AUTOSAR XML (schema 4-0-3)
standard types defined: boolean, float32, float64, sint16, sint32, sint8, uint16, uint32, uint8
package /BSWScheduler/BswImplementations
  bsw implementation bswImplementation0: programming-language=C, sw-version=1.0.0, vendor-id=20, ar-release-version=1.0.0, behavior=Com/InternalBehavior_0, vendor-api-infix=abc
    code-descriptors:
      code Code: artifact-descriptors=autosar-engineering-object={short-label=Label, category=Category}
    resource consumption resourceConsumption
  bsw implementation bswImplementation1: programming-language=C, sw-version=1.0.0, vendor-id=20, ar-release-version=1.0.0, behavior=Can/InternalBehavior_0, vendor-api-infix=abc
    code-descriptors:
      code Code: artifact-descriptors=autosar-engineering-object={short-label=Label, category=Category}
    resource consumption resourceConsumption
  bsw implementation bswImplementation2: programming-language=C, sw-version=1.0.0, vendor-id=20, ar-release-version=1.0.0, behavior=CanIf/InternalBehavior_0, vendor-api-infix=abc
    code-descriptors:
      code Code: artifact-descriptors=autosar-engineering-object={short-label=Label, category=Category}
    resource consumption resourceConsumption
package /BSWScheduler/BswModuleDescriptions
  bsw module description Can: module-id=80, provided-entrys=BswModuleEntryDummy0
    bsw internal behavior InternalBehavior_0
      exclusive area Reentrant
      bsw schedulable entity BswSchedulableEntityDummy: can-enter-exclusive-area=Reentrant, implemented-entry=BswModuleEntryDummy0
  bsw module description CanIf: module-id=60, provided-entrys=BswModuleEntryDummy1
    bsw internal behavior InternalBehavior_0
      exclusive area Reentrant_0
      exclusive area Reentrant_1
      bsw schedulable entity BswSchedulableEntityDummy: can-enter-exclusive-area=[InternalBehavior_0/Reentrant_0, InternalBehavior_0/Reentrant_1], implemented-entry=BswModuleEntryDummy1
  bsw module description Com: module-id=50, provided-entrys=[MainFunctionRx, MainFunctionTx]
    bsw internal behavior InternalBehavior_0
      exclusive area Reentrant_{0..2}
      bsw schedulable entity MainFunctionRx: can-enter-exclusive-area=[InternalBehavior_0/Reentrant_0, InternalBehavior_0/Reentrant_1, Reentrant_2], implemented-entry=MainFunctionRx
      bsw schedulable entity MainFunctionTx: can-enter-exclusive-area=[InternalBehavior_0/Reentrant_0, InternalBehavior_0/Reentrant_1, Reentrant_2], implemented-entry=MainFunctionTx
      bsw timing event TimingEvent_MainFunctionRx: starts-on-event=MainFunctionRx, period=0.1
      bsw timing event TimingEvent_MainFunctionTx: starts-on-event=MainFunctionTx, period=0.1
package /BSWScheduler/BswModuleEntrys
  4 x bsw module entry, all with is-synchronous=true, call-type=SCHEDULED, execution-context=TASK, sw-service-impl-policy=STANDARD:
    BswModuleEntryDummy0: is-reentrant=true
    BswModuleEntryDummy1: is-reentrant=true
    MainFunctionRx: service-id=24, is-reentrant=false
    MainFunctionTx: service-id=25, is-reentrant=false
package /HelloAutosar
  composition sw component type HA_TopLevel
    component SWC1: type=SWC1
    component SWC2: type=SWC2
    connect SWC1.PPort -> SWC2.RPort
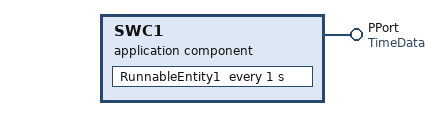
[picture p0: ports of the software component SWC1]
  application sw component type SWC1
    provide port PPort: nonqueued-sender-com-spec{data-element=time, transmission-acknowledge=timeout=0, init-value=Value:0}, provided-interface=TimeData
    behavior IB_SWC1: handle-termination-and-restart=NO-SUPPORT
      timing event TimingEvent: start-on-event=RunnableEntity1, period=1
      runnable RunnableEntity1
        data-send-points:
          access VariableAccess: accessed-variable=PPort.time
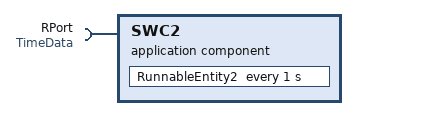
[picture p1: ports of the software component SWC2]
  application sw component type SWC2
    require port RPort: nonqueued-receiver-com-spec{data-element=time, alive-timeout=10, enable-update=true, init-value=Value:0}, required-interface=TimeData
    behavior IB_SWC2: handle-termination-and-restart=NO-SUPPORT
      timing event TimingEvent: start-on-event=RunnableEntity2, period=1
      runnable RunnableEntity2
        data-receive-point-by-arguments:
          access VariableAccess: accessed-variable=RPort.time
package /ImplDataTypes
  impl type IDT_TimeCount: category=VALUE, base-type=uint32
package /Interfaces
  sender receiver interface TimeData
    data time: type=IDT_TimeCount
package /Network
  pdu ISignalIPdu1: unused-bit-pattern=0
    signal ISignal1: 32 bit, data-type-policy=PORT-INTERFACE-DEFINITION
package /System
  ecu instance EcuInstance1: com-configuration-gw-time-base=0.1, com-configuration-rx-time-base=0.1, com-configuration-tx-time-base=0.1, sleep-mode-supported=false, wake-up-over-bus-supported=false
    can communication controller CanCommunicationController: can-controller-attributes=can-controller-configuration={sync-jump-width=1, time-seg-1=1, time-seg-2=1}
  ecu instance EcuInstance2: com-configuration-gw-time-base=0.1, com-configuration-rx-time-base=0.1, com-configuration-tx-time-base=0.1, sleep-mode-supported=false, wake-up-over-bus-supported=false
    can communication controller CanCommunicationController: can-controller-attributes=can-controller-configuration={sync-jump-width=1, time-seg-1=1, time-seg-2=1}
  ecuc value collection EcucValueCollection: ecu-extract=SystemHA, ecuc-values=[Os, Rte, Com, EcuC]
  system SystemHA: system-version=1.0.0
    system mapping SystemMapping
      data-mappings:
        data-element=SWC1.RootSwCompositionPrototype.PPort.time, system-signal=SystemSignal1
        data-element=SWC2.RootSwCompositionPrototype.RPort.time, system-signal=SystemSignal1
      sw-mappings:
        swc to ecu mapping SwcToEcuMapping: component=RootSwCompositionPrototype.SWC1.SWC1, ecu-instance=EcuInstance1
        swc to ecu mapping SwcToEcuMapping1: component=RootSwCompositionPrototype.SWC2.SWC2, ecu-instance=EcuInstance2
    root-software-compositions:
      root sw composition prototype RootSwCompositionPrototype: software-composition=HA_TopLevel
